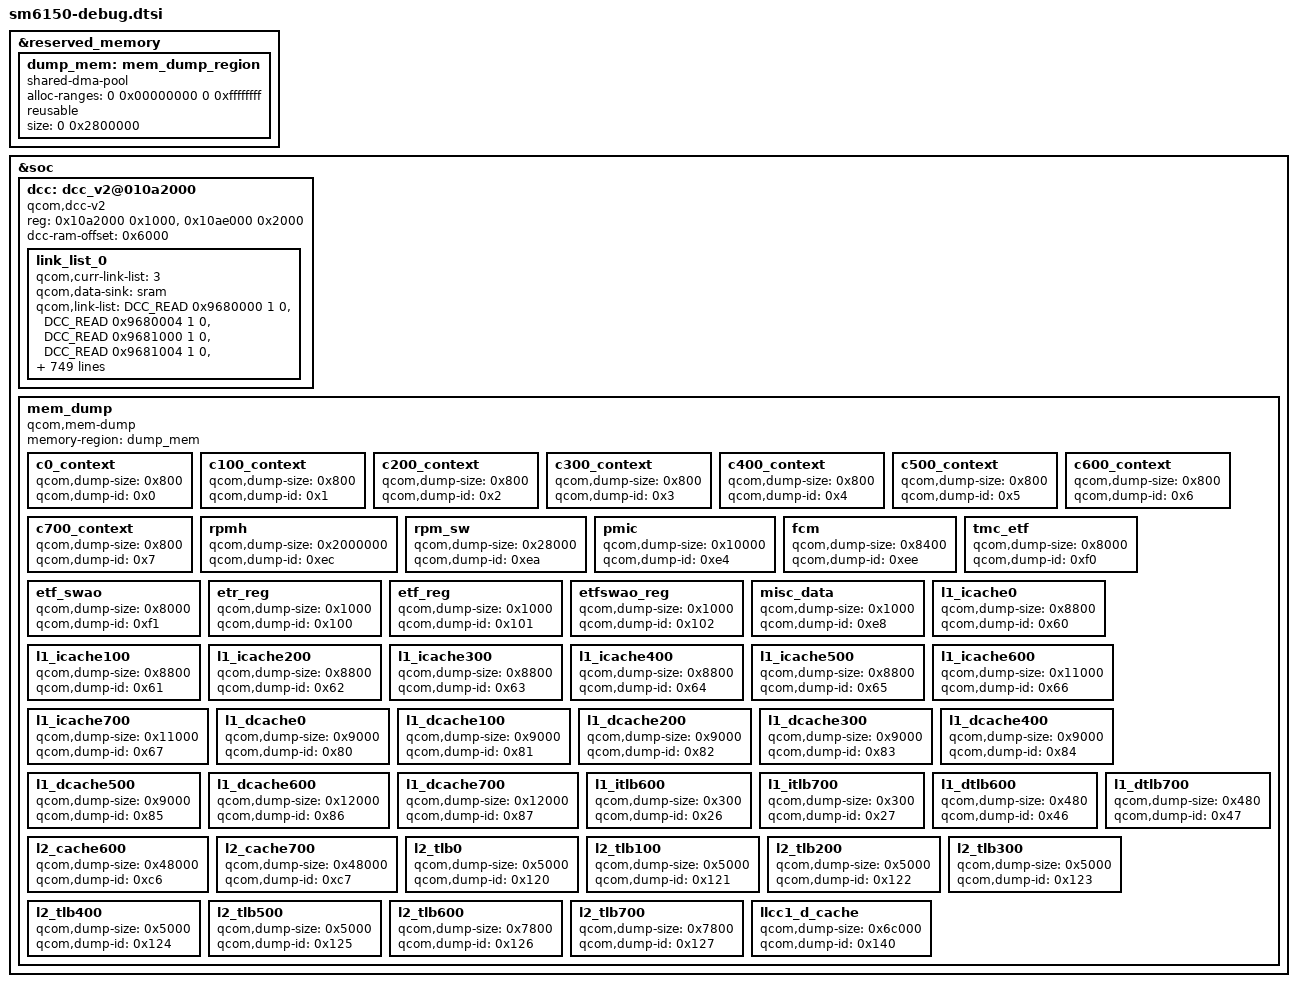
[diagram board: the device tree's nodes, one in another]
#include <dt-bindings/soc/qcom,dcc_v2.h>

&reserved_memory {
	#address-cells = <2>;
	#size-cells = <2>;
	ranges;

	dump_mem: mem_dump_region {
		compatible = "shared-dma-pool";
		alloc-ranges = <0 0x00000000 0 0xffffffff>;
		reusable;
		size = <0 0x2800000>;
	};
};

&soc {
	dcc: dcc_v2@010a2000 {
		compatible = "qcom,dcc-v2";
		reg = <0x10a2000 0x1000>,
		      <0x10ae000 0x2000>;
		reg-names = "dcc-base", "dcc-ram-base";

		dcc-ram-offset = <0x6000>;
		link_list_0 {
			qcom,curr-link-list = <3>;
			qcom,data-sink = "sram";
			qcom,link-list = <DCC_READ 0x9680000 1 0>,
				<DCC_READ 0x9680004 1 0>,
				<DCC_READ 0x9681000 1 0>,
				<DCC_READ 0x9681004 1 0>,
				<DCC_READ 0x9681008 1 0>,
				<DCC_READ 0x968100c 1 0>,
				<DCC_READ 0x9681010 1 0>,
				<DCC_READ 0x9681014 1 0>,
				<DCC_READ 0x968101c 1 0>,
				<DCC_READ 0x9681020 1 0>,
				<DCC_READ 0x9681024 1 0>,
				<DCC_READ 0x9681028 1 0>,
				<DCC_READ 0x968102c 1 0>,
				<DCC_READ 0x9681030 1 0>,
				<DCC_READ 0x9681034 1 0>,
				<DCC_READ 0x968103c 1 0>,
				<DCC_READ 0x9698100 1 0>,
				<DCC_READ 0x9698104 1 0>,
				<DCC_READ 0x9698108 1 0>,
				<DCC_READ 0x9698110 1 0>,
				<DCC_READ 0x9698120 1 0>,
				<DCC_READ 0x9698124 1 0>,
				<DCC_READ 0x9698128 1 0>,
				<DCC_READ 0x969812c 1 0>,
				<DCC_READ 0x9698130 1 0>,
				<DCC_READ 0x9698134 1 0>,
				<DCC_READ 0x9698138 1 0>,
				<DCC_READ 0x969813c 1 0>,
				<DCC_READ 0x9698500 1 0>,
				<DCC_READ 0x9698504 1 0>,
				<DCC_READ 0x9698508 1 0>,
				<DCC_READ 0x969850c 1 0>,
				<DCC_READ 0x9698510 1 0>,
				<DCC_READ 0x9698514 1 0>,
				<DCC_READ 0x9698518 1 0>,
				<DCC_READ 0x969851c 1 0>,
				<DCC_READ 0x9698700 1 0>,
				<DCC_READ 0x9698704 1 0>,
				<DCC_READ 0x9698708 1 0>,
				<DCC_READ 0x969870c 1 0>,
				<DCC_READ 0x9698714 1 0>,
				<DCC_READ 0x9698718 1 0>,
				<DCC_READ 0x969871c 1 0>,
				<DCC_READ 0x1620204 1 0>,
				<DCC_READ 0x1620240 1 0>,
				<DCC_READ 0x1620248 1 0>,
				<DCC_READ 0x1620288 1 0>,
				<DCC_READ 0x162028C 1 0>,
				<DCC_READ 0x1620290 1 0>,
				<DCC_READ 0x1620294 1 0>,
				<DCC_READ 0x16202A8 1 0>,
				<DCC_READ 0x16202AC 1 0>,
				<DCC_READ 0x16202B0 1 0>,
				<DCC_READ 0x16202B4 1 0>,
				<DCC_READ 0x1620300 1 0>,
				<DCC_READ 0x1700204 1 0>,
				<DCC_READ 0x1700240 1 0>,
				<DCC_READ 0x1700248 1 0>,
				<DCC_READ 0x1700288 1 0>,
				<DCC_READ 0x1700290 1 0>,
				<DCC_READ 0x1700300 1 0>,
				<DCC_READ 0x1700304 1 0>,
				<DCC_READ 0x1700308 1 0>,
				<DCC_READ 0x170030C 1 0>,
				<DCC_READ 0x1700310 1 0>,
				<DCC_READ 0x1700314 1 0>,
				<DCC_READ 0x1700C08 1 0>,
				<DCC_READ 0x1700C10 1 0>,
				<DCC_READ 0x1700C20 1 0>,
				<DCC_READ 0x1700C24 1 0>,
				<DCC_READ 0x1700C28 1 0>,
				<DCC_READ 0x1700C2C 1 0>,
				<DCC_READ 0x1700C30 1 0>,
				<DCC_READ 0x1700C34 1 0>,
				<DCC_READ 0x1700C38 1 0>,
				<DCC_READ 0x1700C3C 1 0>,
				<DCC_READ 0x1740240 1 0>,
				<DCC_READ 0x1740248 1 0>,
				<DCC_READ 0x1740288 1 0>,
				<DCC_READ 0x1740290 1 0>,
				<DCC_READ 0x1740300 1 0>,
				<DCC_READ 0x1740304 1 0>,
				<DCC_READ 0x1740308 1 0>,
				<DCC_READ 0x174030C 1 0>,
				<DCC_READ 0x1740310 1 0>,
				<DCC_READ 0x1740314 1 0>,
				<DCC_READ 0x1740004 1 0>,
				<DCC_READ 0x1740008 1 0>,
				<DCC_READ 0x1740010 1 0>,
				<DCC_READ 0x1740020 1 0>,
				<DCC_READ 0x1740024 1 0>,
				<DCC_READ 0x1740028 1 0>,
				<DCC_READ 0x174002C 1 0>,
				<DCC_READ 0x1740030 1 0>,
				<DCC_READ 0x1740034 1 0>,
				<DCC_READ 0x1740038 1 0>,
				<DCC_READ 0x174003C 1 0>,
				<DCC_READ 0x9698204 1 0>,
				<DCC_READ 0x9698240 1 0>,
				<DCC_READ 0x9698244 1 0>,
				<DCC_READ 0x9698248 1 0>,
				<DCC_READ 0x969824C 1 0>,
				<DCC_READ 0x9681010 1 0>,
				<DCC_READ 0x9681014 1 0>,
				<DCC_READ 0x9681018 1 0>,
				<DCC_READ 0x968101C 1 0>,
				<DCC_READ 0x9681020 1 0>,
				<DCC_READ 0x9681024 1 0>,
				<DCC_READ 0x9681028 1 0>,
				<DCC_READ 0x968102C 1 0>,
				<DCC_READ 0x9681030 1 0>,
				<DCC_READ 0x9681034 1 0>,
				<DCC_READ 0x968103C 1 0>,
				<DCC_READ 0x9698100 1 0>,
				<DCC_READ 0x9698104 1 0>,
				<DCC_READ 0x9698108 1 0>,
				<DCC_READ 0x9698110 1 0>,
				<DCC_READ 0x9698120 1 0>,
				<DCC_READ 0x9698124 1 0>,
				<DCC_READ 0x9698128 1 0>,
				<DCC_READ 0x969812C 1 0>,
				<DCC_READ 0x9698130 1 0>,
				<DCC_READ 0x9698134 1 0>,
				<DCC_READ 0x9698138 1 0>,
				<DCC_READ 0x969813C 1 0>,
				<DCC_READ 0x62BE2004 1 0>,
				<DCC_READ 0x62BE2040 1 0>,
				<DCC_READ 0x62BE2048 1 0>,
				<DCC_READ 0x62BE2088 1 0>,
				<DCC_READ 0x62BE2090 1 0>,
				<DCC_READ 0x62BE2100 1 0>,
				<DCC_READ 0x62BE2104 1 0>,
				<DCC_READ 0x62BE2108 1 0>,
				<DCC_READ 0x62BE210C 1 0>,
				<DCC_READ 0x62BE2110 1 0>,
				<DCC_READ 0x62BE2114 1 0>,
				<DCC_READ 0x62BE2118 1 0>,
				<DCC_READ 0x62BE0010 1 0>,
				<DCC_READ 0x62BE0020 1 0>,
				<DCC_READ 0x62BE0024 1 0>,
				<DCC_READ 0x62BE0028 1 0>,
				<DCC_READ 0x62BE002C 1 0>,
				<DCC_READ 0x62BE0030 1 0>,
				<DCC_READ 0x62BE0034 1 0>,
				<DCC_READ 0x62BE0038 1 0>,
				<DCC_READ 0x62BE003C 1 0>,
				<DCC_READ 0x9160204 1 0>,
				<DCC_READ 0x9160240 1 0>,
				<DCC_READ 0x9160248 1 0>,
				<DCC_READ 0x9160288 1 0>,
				<DCC_READ 0x9160290 1 0>,
				<DCC_READ 0x9160300 1 0>,
				<DCC_READ 0x9160304 1 0>,
				<DCC_READ 0x9160308 1 0>,
				<DCC_READ 0x916030C 1 0>,
				<DCC_READ 0x9160310 1 0>,
				<DCC_READ 0x9160314 1 0>,
				<DCC_READ 0x9160318 1 0>,
				<DCC_READ 0x9160008 1 0>,
				<DCC_READ 0x9160010 1 0>,
				<DCC_READ 0x9160020 1 0>,
				<DCC_READ 0x9160024 1 0>,
				<DCC_READ 0x9160028 1 0>,
				<DCC_READ 0x916002C 1 0>,
				<DCC_READ 0x9160030 1 0>,
				<DCC_READ 0x9160034 1 0>,
				<DCC_READ 0x9160038 1 0>,
				<DCC_READ 0x916003C 1 0>,
				<DCC_READ 0x1620500 4 0>,
				<DCC_READ 0x1620700 4 0>,
				<DCC_READ 0x1620300 1 0>,
				<DCC_READ 0x1620F00 2 0>,
				<DCC_READ 0x1620B00 2 0>,
				<DCC_READ 0x1700B00 2 0>,
				<DCC_READ 0x1700700 3 0>,
				<DCC_READ 0x9163100 1 0>,
				<DCC_READ 0x96AA100 1 0>,
				<DCC_READ 0x9050008 1 0>,
				<DCC_READ 0x9050068 1 0>,
				<DCC_READ 0x9050078 1 0>,
				<DCC_READ 0x18200400 1 0>,
				<DCC_READ 0x18200404 1 0>,
				<DCC_READ 0x18200408 1 0>,
				<DCC_READ 0x18200038 1 0>,
				<DCC_READ 0x18200040 1 0>,
				<DCC_READ 0x18200048 1 0>,
				<DCC_READ 0x18220038 1 0>,
				<DCC_READ 0x18220040 1 0>,
				<DCC_READ 0x182200D0 1 0>,
				<DCC_READ 0x18200030 1 0>,
				<DCC_READ 0x18200010 1 0>,
				<DCC_READ 0x1822000c 1 0>,
				<DCC_READ 0x18220d14 1 0>,
				<DCC_READ 0x18220fb4 1 0>,
				<DCC_READ 0x18221254 1 0>,
				<DCC_READ 0x182214f4 1 0>,
				<DCC_READ 0x18221794 1 0>,
				<DCC_READ 0x18221a34 1 0>,
				<DCC_READ 0x18221cd4 1 0>,
				<DCC_READ 0x18221f74 1 0>,
				<DCC_READ 0x18220d18 1 0>,
				<DCC_READ 0x18220fb8 1 0>,
				<DCC_READ 0x18221258 1 0>,
				<DCC_READ 0x182214f8 1 0>,
				<DCC_READ 0x18221798 1 0>,
				<DCC_READ 0x18221a38 1 0>,
				<DCC_READ 0x18221cd8 1 0>,
				<DCC_READ 0x18221f78 1 0>,
				<DCC_READ 0x18220d00 1 0>,
				<DCC_READ 0x18220d04 1 0>,
				<DCC_READ 0x18220d1c 1 0>,
				<DCC_READ 0x18220fbc 1 0>,
				<DCC_READ 0x1822125c 1 0>,
				<DCC_READ 0x182214fc 1 0>,
				<DCC_READ 0x1822179c 1 0>,
				<DCC_READ 0x18221a3c 1 0>,
				<DCC_READ 0x18221cdc 1 0>,
				<DCC_READ 0x18221f7c 1 0>,
				<DCC_READ 0x18221274 1 0>,
				<DCC_READ 0x18221288 1 0>,
				<DCC_READ 0x1822129c 1 0>,
				<DCC_READ 0x182212b0 1 0>,
				<DCC_READ 0x182212c4 1 0>,
				<DCC_READ 0x182212d8 1 0>,
				<DCC_READ 0x182212ec 1 0>,
				<DCC_READ 0x18221300 1 0>,
				<DCC_READ 0x18221314 1 0>,
				<DCC_READ 0x18221328 1 0>,
				<DCC_READ 0x1822133c 1 0>,
				<DCC_READ 0x18221350 1 0>,
				<DCC_READ 0x18221364 1 0>,
				<DCC_READ 0x18221378 1 0>,
				<DCC_READ 0x1822138c 1 0>,
				<DCC_READ 0x182213a0 1 0>,
				<DCC_READ 0x18221514 1 0>,
				<DCC_READ 0x18221528 1 0>,
				<DCC_READ 0x1822153c 1 0>,
				<DCC_READ 0x18221550 1 0>,
				<DCC_READ 0x18221564 1 0>,
				<DCC_READ 0x18221578 1 0>,
				<DCC_READ 0x1822158c 1 0>,
				<DCC_READ 0x182215a0 1 0>,
				<DCC_READ 0x182215b4 1 0>,
				<DCC_READ 0x182215c8 1 0>,
				<DCC_READ 0x182215dc 1 0>,
				<DCC_READ 0x182215f0 1 0>,
				<DCC_READ 0x18221604 1 0>,
				<DCC_READ 0x18221618 1 0>,
				<DCC_READ 0x1822162c 1 0>,
				<DCC_READ 0x18221640 1 0>,
				<DCC_READ 0x182217b4 1 0>,
				<DCC_READ 0x182217c8 1 0>,
				<DCC_READ 0x182217dc 1 0>,
				<DCC_READ 0x182217f0 1 0>,
				<DCC_READ 0x18221804 1 0>,
				<DCC_READ 0x18221818 1 0>,
				<DCC_READ 0x1822182c 1 0>,
				<DCC_READ 0x18221840 1 0>,
				<DCC_READ 0x18221854 1 0>,
				<DCC_READ 0x18221868 1 0>,
				<DCC_READ 0x1822187c 1 0>,
				<DCC_READ 0x18221890 1 0>,
				<DCC_READ 0x182218a4 1 0>,
				<DCC_READ 0x182218b8 1 0>,
				<DCC_READ 0x182218cc 1 0>,
				<DCC_READ 0x182218e0 1 0>,
				<DCC_READ 0x18221a54 1 0>,
				<DCC_READ 0x18221a68 1 0>,
				<DCC_READ 0x18221a7c 1 0>,
				<DCC_READ 0x18221a90 1 0>,
				<DCC_READ 0x18221aa4 1 0>,
				<DCC_READ 0x18221ab8 1 0>,
				<DCC_READ 0x18221acc 1 0>,
				<DCC_READ 0x18221ae0 1 0>,
				<DCC_READ 0x18221af4 1 0>,
				<DCC_READ 0x18221b08 1 0>,
				<DCC_READ 0x18221b1c 1 0>,
				<DCC_READ 0x18221b30 1 0>,
				<DCC_READ 0x18221b44 1 0>,
				<DCC_READ 0x18221b58 1 0>,
				<DCC_READ 0x18221b6c 1 0>,
				<DCC_READ 0x18221b80 1 0>,
				<DCC_READ 0x18221cf4 1 0>,
				<DCC_READ 0x18221d08 1 0>,
				<DCC_READ 0x18221d1c 1 0>,
				<DCC_READ 0x18221d30 1 0>,
				<DCC_READ 0x18221d44 1 0>,
				<DCC_READ 0x18221d58 1 0>,
				<DCC_READ 0x18221d6c 1 0>,
				<DCC_READ 0x18221d80 1 0>,
				<DCC_READ 0x18221d94 1 0>,
				<DCC_READ 0x18221da8 1 0>,
				<DCC_READ 0x18221dbc 1 0>,
				<DCC_READ 0x18221dd0 1 0>,
				<DCC_READ 0x18221de4 1 0>,
				<DCC_READ 0x18221df8 1 0>,
				<DCC_READ 0x18221e0c 1 0>,
				<DCC_READ 0x18221e20 1 0>,
				<DCC_READ 0x18221f94 1 0>,
				<DCC_READ 0x18221fa8 1 0>,
				<DCC_READ 0x18221fbc 1 0>,
				<DCC_READ 0x18221fd0 1 0>,
				<DCC_READ 0x18221fe4 1 0>,
				<DCC_READ 0x18221ff8 1 0>,
				<DCC_READ 0x1822200c 1 0>,
				<DCC_READ 0x18222020 1 0>,
				<DCC_READ 0x18222034 1 0>,
				<DCC_READ 0x18222048 1 0>,
				<DCC_READ 0x1822205c 1 0>,
				<DCC_READ 0x18222070 1 0>,
				<DCC_READ 0x18222084 1 0>,
				<DCC_READ 0x18222098 1 0>,
				<DCC_READ 0x182220ac 1 0>,
				<DCC_READ 0x182220c0 1 0>,
				<DCC_READ 0x18221278 1 0>,
				<DCC_READ 0x1822128c 1 0>,
				<DCC_READ 0x182212a0 1 0>,
				<DCC_READ 0x182212b4 1 0>,
				<DCC_READ 0x182212c8 1 0>,
				<DCC_READ 0x182212dc 1 0>,
				<DCC_READ 0x182212f0 1 0>,
				<DCC_READ 0x18221304 1 0>,
				<DCC_READ 0x18221318 1 0>,
				<DCC_READ 0x1822132c 1 0>,
				<DCC_READ 0x18221340 1 0>,
				<DCC_READ 0x18221354 1 0>,
				<DCC_READ 0x18221368 1 0>,
				<DCC_READ 0x1822137c 1 0>,
				<DCC_READ 0x18221390 1 0>,
				<DCC_READ 0x182213a4 1 0>,
				<DCC_READ 0x18221518 1 0>,
				<DCC_READ 0x1822152c 1 0>,
				<DCC_READ 0x18221540 1 0>,
				<DCC_READ 0x18221554 1 0>,
				<DCC_READ 0x18221568 1 0>,
				<DCC_READ 0x1822157c 1 0>,
				<DCC_READ 0x18221590 1 0>,
				<DCC_READ 0x182215a4 1 0>,
				<DCC_READ 0x182215b8 1 0>,
				<DCC_READ 0x182215cc 1 0>,
				<DCC_READ 0x182215e0 1 0>,
				<DCC_READ 0x182215f4 1 0>,
				<DCC_READ 0x18221608 1 0>,
				<DCC_READ 0x1822161c 1 0>,
				<DCC_READ 0x18221630 1 0>,
				<DCC_READ 0x18221644 1 0>,
				<DCC_READ 0x182217b8 1 0>,
				<DCC_READ 0x182217cc 1 0>,
				<DCC_READ 0x182217e0 1 0>,
				<DCC_READ 0x182217f4 1 0>,
				<DCC_READ 0x18221808 1 0>,
				<DCC_READ 0x1822181c 1 0>,
				<DCC_READ 0x18221830 1 0>,
				<DCC_READ 0x18221844 1 0>,
				<DCC_READ 0x18221858 1 0>,
				<DCC_READ 0x1822186c 1 0>,
				<DCC_READ 0x18221880 1 0>,
				<DCC_READ 0x18221894 1 0>,
				<DCC_READ 0x182218a8 1 0>,
				<DCC_READ 0x182218bc 1 0>,
				<DCC_READ 0x182218d0 1 0>,
				<DCC_READ 0x182218e4 1 0>,
				<DCC_READ 0x18221a58 1 0>,
				<DCC_READ 0x18221a6c 1 0>,
				<DCC_READ 0x18221a80 1 0>,
				<DCC_READ 0x18221a94 1 0>,
				<DCC_READ 0x18221aa8 1 0>,
				<DCC_READ 0x18221abc 1 0>,
				<DCC_READ 0x18221ad0 1 0>,
				<DCC_READ 0x18221ae4 1 0>,
				<DCC_READ 0x18221af8 1 0>,
				<DCC_READ 0x18221b0c 1 0>,
				<DCC_READ 0x18221b20 1 0>,
				<DCC_READ 0x18221b34 1 0>,
				<DCC_READ 0x18221b48 1 0>,
				<DCC_READ 0x18221b5c 1 0>,
				<DCC_READ 0x18221b70 1 0>,
				<DCC_READ 0x18221b84 1 0>,
				<DCC_READ 0x18221cf8 1 0>,
				<DCC_READ 0x18221d0c 1 0>,
				<DCC_READ 0x18221d20 1 0>,
				<DCC_READ 0x18221d34 1 0>,
				<DCC_READ 0x18221d48 1 0>,
				<DCC_READ 0x18221d5c 1 0>,
				<DCC_READ 0x18221d70 1 0>,
				<DCC_READ 0x18221d84 1 0>,
				<DCC_READ 0x18221d98 1 0>,
				<DCC_READ 0x18221dac 1 0>,
				<DCC_READ 0x18221dc0 1 0>,
				<DCC_READ 0x18221dd4 1 0>,
				<DCC_READ 0x18221de8 1 0>,
				<DCC_READ 0x18221dfc 1 0>,
				<DCC_READ 0x18221e10 1 0>,
				<DCC_READ 0x18221e24 1 0>,
				<DCC_READ 0x18221f98 1 0>,
				<DCC_READ 0x18221fac 1 0>,
				<DCC_READ 0x18221fc0 1 0>,
				<DCC_READ 0x18221fd4 1 0>,
				<DCC_READ 0x18221fe8 1 0>,
				<DCC_READ 0x18221ffc 1 0>,
				<DCC_READ 0x18222010 1 0>,
				<DCC_READ 0x18222024 1 0>,
				<DCC_READ 0x18222038 1 0>,
				<DCC_READ 0x1822204c 1 0>,
				<DCC_READ 0x18222060 1 0>,
				<DCC_READ 0x18222074 1 0>,
				<DCC_READ 0x18222088 1 0>,
				<DCC_READ 0x1822209c 1 0>,
				<DCC_READ 0x182220b0 1 0>,
				<DCC_READ 0x182220c4 1 0>,
				<DCC_READ 0x18000024 1 0>,
				<DCC_READ 0x18000040 1 0>,
				<DCC_READ 0x18010024 1 0>,
				<DCC_READ 0x18010040 1 0>,
				<DCC_READ 0x18020024 1 0>,
				<DCC_READ 0x18020040 1 0>,
				<DCC_READ 0x18030024 1 0>,
				<DCC_READ 0x18030040 1 0>,
				<DCC_READ 0x18040024 1 0>,
				<DCC_READ 0x18040040 1 0>,
				<DCC_READ 0x18050024 1 0>,
				<DCC_READ 0x18050040 1 0>,
				<DCC_READ 0x18060024 1 0>,
				<DCC_READ 0x18060040 1 0>,
				<DCC_READ 0x18070024 1 0>,
				<DCC_READ 0x18070040 1 0>,
				<DCC_READ 0x18080024 1 0>,
				<DCC_READ 0x18080040 1 0>,
				<DCC_READ 0x180800F8 1 0>,
				<DCC_READ 0x18080104 1 0>,
				<DCC_READ 0x1808011C 1 0>,
				<DCC_READ 0x18080128 1 0>,
				<DCC_READ 0x90b0280 1 0>,
				<DCC_READ 0x90b0288 1 0>,
				<DCC_READ 0x90b028c 1 0>,
				<DCC_READ 0x90b0290 1 0>,
				<DCC_READ 0x90b0294 1 0>,
				<DCC_READ 0x90b0298 1 0>,
				<DCC_READ 0x90b029c 1 0>,
				<DCC_READ 0x90b02a0 1 0>,
				<DCC_READ 0x18321700 1 0>,
				<DCC_READ 0x18322C18 1 0>,
				<DCC_READ 0x18323700 1 0>,
				<DCC_READ 0x18324C18 1 0>,
				<DCC_READ 0x18325F00 1 0>,
				<DCC_READ 0x18327418 1 0>,
				<DCC_READ 0x9236028 1 0>,
				<DCC_READ 0x923602C 1 0>,
				<DCC_READ 0x9236030 1 0>,
				<DCC_READ 0x9236034 1 0>,
				<DCC_READ 0x9236038 1 0>,
				<DCC_READ 0x9232100 1 0>,
				<DCC_READ 0x92360b0 1 0>,
				<DCC_READ 0x9236044 1 0>,
				<DCC_READ 0x9236048 1 0>,
				<DCC_READ 0x923604c 1 0>,
				<DCC_READ 0x9236050 1 0>,
				<DCC_READ 0x923e030 1 0>,
				<DCC_READ 0x923e034 1 0>,
				<DCC_READ 0x9241000 1 0>,
				<DCC_READ 0x9248058 1 0>,
				<DCC_READ 0x924805c 1 0>,
				<DCC_READ 0x9248060 1 0>,
				<DCC_READ 0x9248064 1 0>,
				<DCC_READ 0x9260410 1 0>,
				<DCC_READ 0x92e0410 1 0>,
				<DCC_READ 0x9260414 1 0>,
				<DCC_READ 0x92e0414 1 0>,
				<DCC_READ 0x9260418 1 0>,
				<DCC_READ 0x92e0418 1 0>,
				<DCC_READ 0x9260420 1 0>,
				<DCC_READ 0x9260424 1 0>,
				<DCC_READ 0x9260430 1 0>,
				<DCC_READ 0x9260440 1 0>,
				<DCC_READ 0x9260448 1 0>,
				<DCC_READ 0x92604a0 1 0>,
				<DCC_READ 0x92e0420 1 0>,
				<DCC_READ 0x92e0424 1 0>,
				<DCC_READ 0x92e0430 1 0>,
				<DCC_READ 0x92e0440 1 0>,
				<DCC_READ 0x92e0448 1 0>,
				<DCC_READ 0x92e04a0 1 0>,
				<DCC_READ 0x9600000 1 0>,
				<DCC_READ 0x9601000 1 0>,
				<DCC_READ 0x9602000 1 0>,
				<DCC_READ 0x9603000 1 0>,
				<DCC_READ 0x9604000 1 0>,
				<DCC_READ 0x9605000 1 0>,
				<DCC_READ 0x9606000 1 0>,
				<DCC_READ 0x9607000 1 0>,
				<DCC_READ 0x9608000 1 0>,
				<DCC_READ 0x9609000 1 0>,
				<DCC_READ 0x960a000 1 0>,
				<DCC_READ 0x960b000 1 0>,
				<DCC_READ 0x960c000 1 0>,
				<DCC_READ 0x960d000 1 0>,
				<DCC_READ 0x960e000 1 0>,
				<DCC_READ 0x960f000 1 0>,
				<DCC_READ 0x9610000 1 0>,
				<DCC_READ 0x9611000 1 0>,
				<DCC_READ 0x9612000 1 0>,
				<DCC_READ 0x9613000 1 0>,
				<DCC_READ 0x9614000 1 0>,
				<DCC_READ 0x9615000 1 0>,
				<DCC_READ 0x9616000 1 0>,
				<DCC_READ 0x9617000 1 0>,
				<DCC_READ 0x9618000 1 0>,
				<DCC_READ 0x9619000 1 0>,
				<DCC_READ 0x961a000 1 0>,
				<DCC_READ 0x961b000 1 0>,
				<DCC_READ 0x961c000 1 0>,
				<DCC_READ 0x961d000 1 0>,
				<DCC_READ 0x961e000 1 0>,
				<DCC_READ 0x961f000 1 0>,
				<DCC_READ 0x9600004 1 0>,
				<DCC_READ 0x9601004 1 0>,
				<DCC_READ 0x9602004 1 0>,
				<DCC_READ 0x9603004 1 0>,
				<DCC_READ 0x9604004 1 0>,
				<DCC_READ 0x9605004 1 0>,
				<DCC_READ 0x9606004 1 0>,
				<DCC_READ 0x9607004 1 0>,
				<DCC_READ 0x9608004 1 0>,
				<DCC_READ 0x9609004 1 0>,
				<DCC_READ 0x960a004 1 0>,
				<DCC_READ 0x960b004 1 0>,
				<DCC_READ 0x960c004 1 0>,
				<DCC_READ 0x960d004 1 0>,
				<DCC_READ 0x960e004 1 0>,
				<DCC_READ 0x960f004 1 0>,
				<DCC_READ 0x9610004 1 0>,
				<DCC_READ 0x9611004 1 0>,
				<DCC_READ 0x9612004 1 0>,
				<DCC_READ 0x9613004 1 0>,
				<DCC_READ 0x9614004 1 0>,
				<DCC_READ 0x9615004 1 0>,
				<DCC_READ 0x9616004 1 0>,
				<DCC_READ 0x9617004 1 0>,
				<DCC_READ 0x9618004 1 0>,
				<DCC_READ 0x9619004 1 0>,
				<DCC_READ 0x961a004 1 0>,
				<DCC_READ 0x961b004 1 0>,
				<DCC_READ 0x961c004 1 0>,
				<DCC_READ 0x961d004 1 0>,
				<DCC_READ 0x961e004 1 0>,
				<DCC_READ 0x961f004 1 0>,
				<DCC_READ 0x9266418 1 0>,
				<DCC_READ 0x92e6418 1 0>,
				<DCC_READ 0x9265804 1 0>,
				<DCC_READ 0x92e5804 1 0>,
				<DCC_READ 0x92604b8 1 0>,
				<DCC_READ 0x92e04b8 1 0>,
				<DCC_READ 0x0C201244 1 0>,
				<DCC_READ 0x0C202244 1 0>,
				<DCC_READ 0x18100C18 1 0>,
				<DCC_READ 0x18101C18 1 0>,
				<DCC_READ 0x18300000 1 0>,
				<DCC_READ 0x183A3A84 2 0>,
				<DCC_READ 0x18393A84 2 0>,
				<DCC_READ 0x00100000 1 0>,
				<DCC_READ 0x00100004 1 0>,
				<DCC_READ 0x00100008 1 0>,
				<DCC_READ 0x0010000C 1 0>,
				<DCC_READ 0x00100010 1 0>,
				<DCC_READ 0x00100014 1 0>,
				<DCC_READ 0x00100018 1 0>,
				<DCC_READ 0x0010001C 1 0>,
				<DCC_READ 0x00100020 1 0>,
				<DCC_READ 0x00100024 1 0>,
				<DCC_READ 0x00100028 1 0>,
				<DCC_READ 0x0010002C 1 0>,
				<DCC_READ 0x00100030 1 0>,
				<DCC_READ 0x00100034 1 0>,
				<DCC_READ 0x00100100 1 0>,
				<DCC_READ 0x00100104 1 0>,
				<DCC_READ 0x00100108 1 0>,
				<DCC_READ 0x0010010C 1 0>,
				<DCC_READ 0x00101000 1 0>,
				<DCC_READ 0x00101004 1 0>,
				<DCC_READ 0x00101008 1 0>,
				<DCC_READ 0x0010100C 1 0>,
				<DCC_READ 0x00101010 1 0>,
				<DCC_READ 0x00101014 1 0>,
				<DCC_READ 0x00101018 1 0>,
				<DCC_READ 0x0010101C 1 0>,
				<DCC_READ 0x00101020 1 0>,
				<DCC_READ 0x00101024 1 0>,
				<DCC_READ 0x00101028 1 0>,
				<DCC_READ 0x0010102C 1 0>,
				<DCC_READ 0x00101030 1 0>,
				<DCC_READ 0x00101034 1 0>,
				<DCC_READ 0x00102000 1 0>,
				<DCC_READ 0x00102004 1 0>,
				<DCC_READ 0x00102008 1 0>,
				<DCC_READ 0x0010200C 1 0>,
				<DCC_READ 0x00102010 1 0>,
				<DCC_READ 0x00102014 1 0>,
				<DCC_READ 0x00102018 1 0>,
				<DCC_READ 0x0010201C 1 0>,
				<DCC_READ 0x00102020 1 0>,
				<DCC_READ 0x00102024 1 0>,
				<DCC_READ 0x00102028 1 0>,
				<DCC_READ 0x0010202C 1 0>,
				<DCC_READ 0x00102030 1 0>,
				<DCC_READ 0x00102034 1 0>,
				<DCC_READ 0x00103000 1 0>,
				<DCC_READ 0x00103004 1 0>,
				<DCC_READ 0x00103008 1 0>,
				<DCC_READ 0x0010300C 1 0>,
				<DCC_READ 0x00103010 1 0>,
				<DCC_READ 0x00103014 1 0>,
				<DCC_READ 0x00103018 1 0>,
				<DCC_READ 0x0010301C 1 0>,
				<DCC_READ 0x00103020 1 0>,
				<DCC_READ 0x00103024 1 0>,
				<DCC_READ 0x00103028 1 0>,
				<DCC_READ 0x0010302C 1 0>,
				<DCC_READ 0x00103030 1 0>,
				<DCC_READ 0x00103034 1 0>,
				<DCC_READ 0x00113000 1 0>,
				<DCC_READ 0x00113004 1 0>,
				<DCC_READ 0x00113008 1 0>,
				<DCC_READ 0x0011300C 1 0>,
				<DCC_READ 0x00113010 1 0>,
				<DCC_READ 0x00113014 1 0>,
				<DCC_READ 0x00113018 1 0>,
				<DCC_READ 0x0011301C 1 0>,
				<DCC_READ 0x00113020 1 0>,
				<DCC_READ 0x00113024 1 0>,
				<DCC_READ 0x00113028 1 0>,
				<DCC_READ 0x0011302C 1 0>,
				<DCC_READ 0x00113030 1 0>,
				<DCC_READ 0x00113034 1 0>,
				<DCC_READ 0x0011A000 1 0>,
				<DCC_READ 0x0011A004 1 0>,
				<DCC_READ 0x0011A008 1 0>,
				<DCC_READ 0x0011A00C 1 0>,
				<DCC_READ 0x0011A010 1 0>,
				<DCC_READ 0x0011A014 1 0>,
				<DCC_READ 0x0011A018 1 0>,
				<DCC_READ 0x0011A01C 1 0>,
				<DCC_READ 0x0011A020 1 0>,
				<DCC_READ 0x0011A024 1 0>,
				<DCC_READ 0x0011A028 1 0>,
				<DCC_READ 0x0011A02C 1 0>,
				<DCC_READ 0x0011A030 1 0>,
				<DCC_READ 0x0011A034 1 0>,
				<DCC_READ 0x0011B000 1 0>,
				<DCC_READ 0x0011B004 1 0>,
				<DCC_READ 0x0011B008 1 0>,
				<DCC_READ 0x0011B00C 1 0>,
				<DCC_READ 0x0011B010 1 0>,
				<DCC_READ 0x0011B014 1 0>,
				<DCC_READ 0x0011B018 1 0>,
				<DCC_READ 0x0011B01C 1 0>,
				<DCC_READ 0x0011B020 1 0>,
				<DCC_READ 0x0011B024 1 0>,
				<DCC_READ 0x0011B028 1 0>,
				<DCC_READ 0x0011B02C 1 0>,
				<DCC_READ 0x0011B030 1 0>,
				<DCC_READ 0x0011B034 1 0>,
				<DCC_READ 0x00174000 1 0>,
				<DCC_READ 0x00174004 1 0>,
				<DCC_READ 0x00174008 1 0>,
				<DCC_READ 0x0017400C 1 0>,
				<DCC_READ 0x00174010 1 0>,
				<DCC_READ 0x00174014 1 0>,
				<DCC_READ 0x00174018 1 0>,
				<DCC_READ 0x0017401C 1 0>,
				<DCC_READ 0x00174020 1 0>,
				<DCC_READ 0x00174024 1 0>,
				<DCC_READ 0x00174028 1 0>,
				<DCC_READ 0x0017402C 1 0>,
				<DCC_READ 0x00174030 1 0>,
				<DCC_READ 0x00174034 1 0>,
				<DCC_READ 0x00176000 1 0>,
				<DCC_READ 0x00176004 1 0>,
				<DCC_READ 0x00176008 1 0>,
				<DCC_READ 0x0017600C 1 0>,
				<DCC_READ 0x00176010 1 0>,
				<DCC_READ 0x00176014 1 0>,
				<DCC_READ 0x00176018 1 0>,
				<DCC_READ 0x0017601C 1 0>,
				<DCC_READ 0x00176020 1 0>,
				<DCC_READ 0x00176024 1 0>,
				<DCC_READ 0x00176028 1 0>,
				<DCC_READ 0x0017602C 1 0>,
				<DCC_READ 0x00176030 1 0>,
				<DCC_READ 0x00176034 1 0>,
				<DCC_READ 0x0010401C 1 0>,
				<DCC_READ 0x00183024 1 0>,
				<DCC_READ 0x00144168 1 0>,
				<DCC_READ 0x0011702C 1 0>,
				<DCC_READ 0x0010904C 1 0>,
				<DCC_READ 0x00189038 1 0>,
				<DCC_READ 0x001443E8 1 0>,
				<DCC_READ 0x001442B8 1 0>,
				<DCC_READ 0x00105060 1 0>,
				<DCC_READ 0x00141024 1 0>,
				<DCC_READ 0x00145038 1 0>,
				<DCC_READ 0x00109004 1 0>,
				<DCC_READ 0x00189004 1 0>,
				<DCC_READ 0x00190004 1 0>,
				<DCC_READ 0x0C2A0000 1 0>,
				<DCC_READ 0x0C2A0004 1 0>,
				<DCC_READ 0x0C2A0008 1 0>,
				<DCC_READ 0x0C2A000C 1 0>,
				<DCC_READ 0x0C2A0010 1 0>,
				<DCC_READ 0x0C2A0014 1 0>,
				<DCC_READ 0x0C2A0018 1 0>,
				<DCC_READ 0x0C2A001C 1 0>,
				<DCC_READ 0x0C2A0020 1 0>,
				<DCC_READ 0x0C2A0024 1 0>,
				<DCC_READ 0x0C2A0028 1 0>,
				<DCC_READ 0x0C2A002C 1 0>,
				<DCC_READ 0x0C2A0030 1 0>,
				<DCC_READ 0x0C2A0034 1 0>,
				<DCC_READ 0x0C2A1000 1 0>,
				<DCC_READ 0x0C2A1004 1 0>,
				<DCC_READ 0x0C2A1008 1 0>,
				<DCC_READ 0x0C2A100C 1 0>,
				<DCC_READ 0x0C2A1010 1 0>,
				<DCC_READ 0x0C2A1014 1 0>,
				<DCC_READ 0x0C2A1018 1 0>,
				<DCC_READ 0x0C2A101C 1 0>,
				<DCC_READ 0x0C2A1020 1 0>,
				<DCC_READ 0x0C2A1024 1 0>,
				<DCC_READ 0x0C2A1028 1 0>,
				<DCC_READ 0x0C2A102C 1 0>,
				<DCC_READ 0x0C2A1030 1 0>,
				<DCC_READ 0x0C2A2260 1 0>,
				<DCC_READ 0x0C2A2264 1 0>,
				<DCC_READ 0x0C2A3008 1 0>,
				<DCC_READ 0x0C2A300C 1 0>,
				<DCC_READ 0x0C2A3010 1 0>,
				<DCC_READ 0x0C2A3014 1 0>,
				<DCC_READ 0x0C2A3024 1 0>,
				<DCC_READ 0x0C2A2034 1 0>,
				<DCC_READ 0x0C2A214C 1 0>,
				<DCC_READ 0x0C2A2150 1 0>,
				<DCC_READ 0x0C2A2154 1 0>,
				<DCC_READ 0x0C2630A0 4 0>,
				<DCC_READ 0x0C2630B0 4 0>,
				<DCC_READ 0x0C2630C0 4 0>,
				<DCC_READ 0x0C2630D0 4 0>,
				<DCC_READ 0x1800005C 1 0>,
				<DCC_READ 0x1801005C 1 0>,
				<DCC_READ 0x1802005C 1 0>,
				<DCC_READ 0x1803005C 1 0>,
				<DCC_READ 0x1804005C 1 0>,
				<DCC_READ 0x1805005C 1 0>,
				<DCC_READ 0x1806005C 1 0>,
				<DCC_READ 0x1807005C 1 0>;
		};
	};

	mem_dump {
		compatible = "qcom,mem-dump";
		memory-region = <&dump_mem>;

		c0_context {
			qcom,dump-size = <0x800>;
			qcom,dump-id = <0x0>;
		};

		c100_context {
			qcom,dump-size = <0x800>;
			qcom,dump-id = <0x1>;
		};

		c200_context {
			qcom,dump-size = <0x800>;
			qcom,dump-id = <0x2>;
		};

		c300_context {
			qcom,dump-size = <0x800>;
			qcom,dump-id = <0x3>;
		};

		c400_context {
			qcom,dump-size = <0x800>;
			qcom,dump-id = <0x4>;
		};

		c500_context {
			qcom,dump-size = <0x800>;
			qcom,dump-id = <0x5>;
		};

		c600_context {
			qcom,dump-size = <0x800>;
			qcom,dump-id = <0x6>;
		};

		c700_context {
			qcom,dump-size = <0x800>;
			qcom,dump-id = <0x7>;
		};

		rpmh {
			qcom,dump-size = <0x2000000>;
			qcom,dump-id = <0xec>;
		};

		rpm_sw {
			qcom,dump-size = <0x28000>;
			qcom,dump-id = <0xea>;
		};

		pmic {
			qcom,dump-size = <0x10000>;
			qcom,dump-id = <0xe4>;
		};

		fcm {
			qcom,dump-size = <0x8400>;
			qcom,dump-id = <0xee>;
		};

		tmc_etf {
			qcom,dump-size = <0x8000>;
			qcom,dump-id = <0xf0>;
		};

		etf_swao {
			qcom,dump-size = <0x8000>;
			qcom,dump-id = <0xf1>;
		};

		etr_reg {
			qcom,dump-size = <0x1000>;
			qcom,dump-id = <0x100>;
		};

		etf_reg {
			qcom,dump-size = <0x1000>;
			qcom,dump-id = <0x101>;
		};

		etfswao_reg {
			qcom,dump-size = <0x1000>;
			qcom,dump-id = <0x102>;
		};

		misc_data {
			qcom,dump-size = <0x1000>;
			qcom,dump-id = <0xe8>;
		};

		l1_icache0 {
			qcom,dump-size = <0x8800>;
			qcom,dump-id = <0x60>;
		};

		l1_icache100 {
			qcom,dump-size = <0x8800>;
			qcom,dump-id = <0x61>;
		};

		l1_icache200 {
			qcom,dump-size = <0x8800>;
			qcom,dump-id = <0x62>;
		};

		l1_icache300 {
			qcom,dump-size = <0x8800>;
			qcom,dump-id = <0x63>;
		};

		l1_icache400 {
			qcom,dump-size = <0x8800>;
			qcom,dump-id = <0x64>;
		};

		l1_icache500 {
			qcom,dump-size = <0x8800>;
			qcom,dump-id = <0x65>;
		};

		l1_icache600 {
			qcom,dump-size = <0x11000>;
			qcom,dump-id = <0x66>;
		};

		l1_icache700 {
			qcom,dump-size = <0x11000>;
			qcom,dump-id = <0x67>;
		};

		l1_dcache0 {
			qcom,dump-size = <0x9000>;
			qcom,dump-id = <0x80>;
		};

		l1_dcache100 {
			qcom,dump-size = <0x9000>;
			qcom,dump-id = <0x81>;
		};

		l1_dcache200 {
			qcom,dump-size = <0x9000>;
			qcom,dump-id = <0x82>;
		};

		l1_dcache300 {
			qcom,dump-size = <0x9000>;
			qcom,dump-id = <0x83>;
		};

		l1_dcache400 {
			qcom,dump-size = <0x9000>;
			qcom,dump-id = <0x84>;
		};

		l1_dcache500 {
			qcom,dump-size = <0x9000>;
			qcom,dump-id = <0x85>;
		};

		l1_dcache600 {
			qcom,dump-size = <0x12000>;
			qcom,dump-id = <0x86>;
		};

		l1_dcache700 {
			qcom,dump-size = <0x12000>;
			qcom,dump-id = <0x87>;
		};

		l1_itlb600 {
			qcom,dump-size = <0x300>;
			qcom,dump-id = <0x26>;
		};

		l1_itlb700 {
			qcom,dump-size = <0x300>;
			qcom,dump-id = <0x27>;
		};

		l1_dtlb600 {
			qcom,dump-size = <0x480>;
			qcom,dump-id = <0x46>;
		};

		l1_dtlb700 {
			qcom,dump-size = <0x480>;
			qcom,dump-id = <0x47>;
		};

		l2_cache600 {
			qcom,dump-size = <0x48000>;
			qcom,dump-id = <0xc6>;
		};

		l2_cache700 {
			qcom,dump-size = <0x48000>;
			qcom,dump-id = <0xc7>;
		};

		l2_tlb0 {
			qcom,dump-size = <0x5000>;
			qcom,dump-id = <0x120>;
		};

		l2_tlb100 {
			qcom,dump-size = <0x5000>;
			qcom,dump-id = <0x121>;
		};

		l2_tlb200 {
			qcom,dump-size = <0x5000>;
			qcom,dump-id = <0x122>;
		};

		l2_tlb300 {
			qcom,dump-size = <0x5000>;
			qcom,dump-id = <0x123>;
		};

		l2_tlb400 {
			qcom,dump-size = <0x5000>;
			qcom,dump-id = <0x124>;
		};

		l2_tlb500 {
			qcom,dump-size = <0x5000>;
			qcom,dump-id = <0x125>;
		};

		l2_tlb600 {
			qcom,dump-size = <0x7800>;
			qcom,dump-id = <0x126>;
		};

		l2_tlb700 {
			qcom,dump-size = <0x7800>;
			qcom,dump-id = <0x127>;
		};

		llcc1_d_cache {
			qcom,dump-size = <0x6c000>;
			qcom,dump-id = <0x140>;
		};
	};
};
